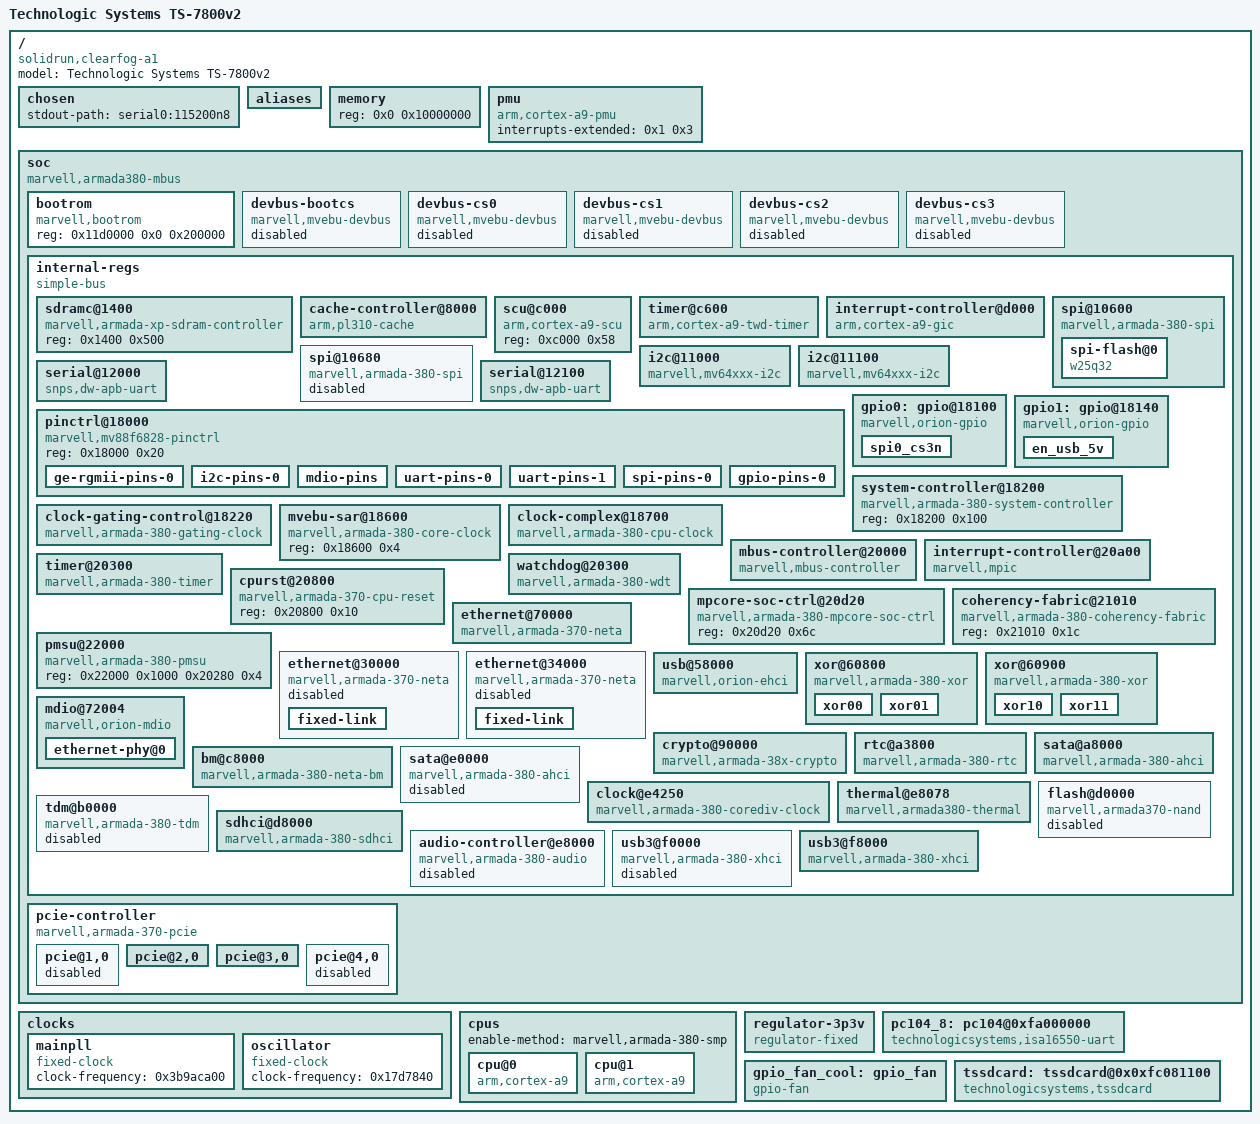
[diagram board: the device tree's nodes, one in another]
/dts-v1/;
#include <dt-bindings/gpio/gpio.h>

/ {
	#address-cells = <0x1>;
	#size-cells = <0x1>;
	model = "Technologic Systems TS-7800v2";
	compatible = "solidrun,clearfog-a1", "marvell,armada388", "marvell,armada385", "marvell,armada380";

	chosen {
		stdout-path = "serial0:115200n8";
	};

	aliases {
		gpio0 = "/soc/internal-regs/gpio@18100";
		gpio1 = "/soc/internal-regs/gpio@18140";
		serial0 = "/soc/internal-regs/serial@12000";
		serial1 = "/soc/internal-regs/serial@12100";
		ethernet1 = "/soc/internal-regs/ethernet@70000";
		ethernet2 = "/soc/internal-regs/ethernet@30000";
		ethernet3 = "/soc/internal-regs/ethernet@34000";
	};

	memory {
		device_type = "memory";
		reg = <0x0 0x10000000>;
	};

	pmu {
		compatible = "arm,cortex-a9-pmu";
		interrupts-extended = <0x1 0x3>;
	};

	soc {
		compatible = "marvell,armada380-mbus", "simple-bus";
		#address-cells = <0x2>;
		#size-cells = <0x1>;
		controller = <0x2>;
		interrupt-parent = <0x3>;
		pcie-mem-aperture = <0xf8000000 0x7e00000>;
		pcie-io-aperture = <0xffe00000 0x100000>;
		ranges = <0xf0010000 0x0 0xf1000000 0x100000 0x11d0000 0x0 0xfff00000 0x100000 0x9190000 0x0 0xf1100000 0x10000 0x9150000 0x0 0xf1110000 0x10000 0xc040000 0x0 0xf1200000 0x100000>;

		bootrom {
			compatible = "marvell,bootrom";
			reg = <0x11d0000 0x0 0x200000>;
		};

		devbus-bootcs {
			compatible = "marvell,mvebu-devbus";
			reg = <0xf0010000 0x10400 0x8>;
			ranges = <0x0 0x12f0000 0x0 0xffffffff>;
			#address-cells = <0x1>;
			#size-cells = <0x1>;
			clocks = <0x4 0x0>;
			status = "disabled";
		};

		devbus-cs0 {
			compatible = "marvell,mvebu-devbus";
			reg = <0xf0010000 0x10408 0x8>;
			ranges = <0x0 0x13e0000 0x0 0xffffffff>;
			#address-cells = <0x1>;
			#size-cells = <0x1>;
			clocks = <0x4 0x0>;
			status = "disabled";
		};

		devbus-cs1 {
			compatible = "marvell,mvebu-devbus";
			reg = <0xf0010000 0x10410 0x8>;
			ranges = <0x0 0x13d0000 0x0 0xffffffff>;
			#address-cells = <0x1>;
			#size-cells = <0x1>;
			clocks = <0x4 0x0>;
			status = "disabled";
		};

		devbus-cs2 {
			compatible = "marvell,mvebu-devbus";
			reg = <0xf0010000 0x10418 0x8>;
			ranges = <0x0 0x13b0000 0x0 0xffffffff>;
			#address-cells = <0x1>;
			#size-cells = <0x1>;
			clocks = <0x4 0x0>;
			status = "disabled";
		};

		devbus-cs3 {
			compatible = "marvell,mvebu-devbus";
			reg = <0xf0010000 0x10420 0x8>;
			ranges = <0x0 0x1370000 0x0 0xffffffff>;
			#address-cells = <0x1>;
			#size-cells = <0x1>;
			clocks = <0x4 0x0>;
			status = "disabled";
		};

		internal-regs {
			compatible = "simple-bus";
			#address-cells = <0x1>;
			#size-cells = <0x1>;
			ranges = <0x0 0xf0010000 0x0 0x100000>;

			sdramc@1400 {
				compatible = "marvell,armada-xp-sdram-controller";
				reg = <0x1400 0x500>;
			};

			cache-controller@8000 {
				compatible = "arm,pl310-cache";
				reg = <0x8000 0x1000>;
				cache-unified;
				cache-level = <0x2>;
				arm,double-linefill-incr = <0x1>;
				arm,double-linefill-wrap = <0x0>;
				arm,double-linefill = <0x1>;
				prefetch-data = <0x1>;
			};

			scu@c000 {
				compatible = "arm,cortex-a9-scu";
				reg = <0xc000 0x58>;
			};

			timer@c600 {
				compatible = "arm,cortex-a9-twd-timer";
				reg = <0xc600 0x20>;
				interrupts = <0x1 0xd 0x301>;
				clocks = <0x4 0x2>;
			};

			interrupt-controller@d000 {
				compatible = "arm,cortex-a9-gic";
				#interrupt-cells = <0x3>;
				#size-cells = <0x0>;
				interrupt-controller;
				reg = <0xd000 0x1000 0xc100 0x100>;
				linux,phandle = <0x3>;
				phandle = <0x3>;
			};

			spi@10600 {
				compatible = "marvell,armada-380-spi", "marvell,orion-spi";
				reg = <0x10600 0x50>;
				#address-cells = <0x1>;
				#size-cells = <0x0>;
				cell-index = <0x0>;
				interrupts = <0x0 0x1 0x4>;
				clocks = <0x4 0x0>;
				status = "okay";
				cs-gpios = <0>, <0>, <0>, <&gpio0 28 0>;

				spi-flash@0 {
					#address-cells = <0x1>;
					#size-cells = <0x1>;
					compatible = "w25q32", "jedec,spi-nor";
					reg = <0x3>;
					spi-max-frequency = <0x2dc6c0>;
					status = "okay";
				};
			};

			spi@10680 {
				compatible = "marvell,armada-380-spi", "marvell,orion-spi";
				reg = <0x10680 0x50>;
				#address-cells = <0x1>;
				#size-cells = <0x0>;
				cell-index = <0x1>;
				interrupts = <0x0 0x3f 0x4>;
				clocks = <0x4 0x0>;
				status = "disabled";
				pinctrl-0 = <0x5 0x6 0x7>;
				pinctrl-names = "default";

//				spi-flash@3 {
//					#address-cells = <0x1>;
//					#size-cells = <0x1>;
//					compatible = "w25q32", "jedec,spi-nor";
//					reg = <0x0>;
//					spi-max-frequency = <0x2dc6c0>;
//					status = "okay";
//				};

//				slic@1 {
//					#address-cells = <0x1>;
//					#size-cells = <0x0>;
//					compatible = "mv_slic";
//					reg = <0x1>;
//					spi-max-frequency = <0x2dc6c0>;
//					spi-1byte-cs;
//					spi-cpol;
//					spi-cpha;
//				};
			};

			i2c@11000 {
				compatible = "marvell,mv64xxx-i2c";
				reg = <0x11000 0x20>;
				#address-cells = <0x1>;
				#size-cells = <0x0>;
				interrupts = <0x0 0x2 0x4>;
				timeout-ms = <0x3e8>;
				clocks = <0x4 0x0>;
				status = "okay";
				clock-frequency = <0x186a0>;
				pinctrl-0 = <0x8>;
				pinctrl-names = "default";

//				gpio-expander@20 {
//					compatible = "nxp,pca9555";
//					gpio-controller;
//					#gpio-cells = <0x2>;
//					reg = <0x20>;
//					linux,phandle = <0x1c>;
//					phandle = <0x1c>;
//
//					pcie1_0_clkreq {
//						gpio-hog;
//						gpios = <0x0 0x1>;
//						input;
//						line-name = "pcie1.0-clkreq";
//					};
//
//					pcie1_0_w_disable {
//						gpio-hog;
//						gpios = <0x3 0x1>;
//						output-low;
//						line-name = "pcie1.0-w-disable";
//					};
//
//					pcie2_0_clkreq {
//						gpio-hog;
//						gpios = <0x4 0x1>;
//						input;
//						line-name = "pcie2.0-clkreq";
//					};
//
//					pcie2_0_w_disable {
//						gpio-hog;
//						gpios = <0x7 0x1>;
//						output-low;
//						line-name = "pcie2.0-w-disable";
//					};
//
//					usb3_ilimit {
//						gpio-hog;
//						gpios = <0x5 0x1>;
//						input;
//						line-name = "usb3-current-limit";
//					};
//
//					usb3_power {
//						gpio-hog;
//						gpios = <0x6 0x0>;
//						output-high;
//						line-name = "usb3-power";
//					};
//
//					m2_devslp {
//						gpio-hog;
//						gpios = <0xb 0x0>;
//						output-low;
//						line-name = "m.2 devslp";
//					};
//
//					sfp_los {
//						gpio-hog;
//						gpios = <0xc 0x0>;
//						input;
//						line-name = "sfp-los";
//					};
//
//					sfp_tx_fault {
//						gpio-hog;
//						gpios = <0xd 0x0>;
//						input;
//						line-name = "sfp-tx-fault";
//					};
//
//					sfp_tx_disable {
//						gpio-hog;
//						gpios = <0xe 0x0>;
//						output-low;
//						line-name = "sfp-tx-disable";
//					};
//
//					sfp_mod_def0 {
//						gpio-hog;
//						gpios = <0xf 0x1>;
//						input;
//						line-name = "sfp-mod-def0";
//					};
//				};
//
//				mcp3021@4c {
//					compatible = "microchip,mcp3021";
//					reg = <0x4c>;
//				};
			};

			i2c@11100 {
				compatible = "marvell,mv64xxx-i2c";
				reg = <0x11100 0x20>;
				#address-cells = <0x1>;
				#size-cells = <0x0>;
				interrupts = <0x0 0x3 0x4>;
				timeout-ms = <0x3e8>;
				clocks = <0x4 0x0>;
				status = "okay";
				clock-frequency = <0x186a0>;
				pinctrl-0 = <0x9>;
				pinctrl-names = "default";
			};

			serial@12000 {
				compatible = "snps,dw-apb-uart";
				reg = <0x12000 0x100>;
				reg-shift = <0x2>;
				interrupts = <0x0 0xc 0x4>;
				reg-io-width = <0x1>;
				clocks = <0x4 0x0>;
				status = "okay";
				pinctrl-0 = <0xa>;
				pinctrl-names = "default";
			};

			serial@12100 {
				compatible = "snps,dw-apb-uart";
				reg = <0x12100 0x100>;
				reg-shift = <0x2>;
				interrupts = <0x0 0xd 0x4>;
				reg-io-width = <0x1>;
				clocks = <0x4 0x0>;
				status = "okay";
				pinctrl-0 = <0xb>;
				pinctrl-names = "default";
			};

			pinctrl@18000 {
				reg = <0x18000 0x20>;
				compatible = "marvell,mv88f6828-pinctrl";


				ge-rgmii-pins-0 {
					marvell,pins = "mpp6", "mpp7", "mpp8", "mpp9", "mpp10", "mpp11", "mpp12", "mpp13", "mpp14", "mpp15", "mpp16", "mpp17";
					marvell,function = "ge0";
					linux,phandle = <0xe>;
					phandle = <0xe>;
				};

				i2c-pins-0 {
					marvell,pins = "mpp2", "mpp3";
					marvell,function = "i2c0";
					linux,phandle = <0x8>;
					phandle = <0x8>;
				};

				mdio-pins {
					marvell,pins = "mpp4", "mpp5";
					marvell,function = "ge";
					linux,phandle = <0x11>;
					phandle = <0x11>;
				};

				uart-pins-0 {
					marvell,pins = "mpp0", "mpp1";
					marvell,function = "ua0";
					linux,phandle = <0xa>;
					phandle = <0xa>;
				};

				uart-pins-1 {
					marvell,pins = "mpp19", "mpp20";
					marvell,function = "ua1";
				};

				spi-pins-0 {
					marvell,pins = "mpp22", "mpp23", "mpp24", "mpp25", "mpp26", "mpp27";
					marvell,function = "spi0";
				};

				gpio-pins-0 {
					marvell,pins = "mpp28", "mpp45";
					marvell,function = "gpio";
				};


			};

			gpio0: gpio@18100 {
				compatible = "marvell,orion-gpio";
				reg = <0x18100 0x40>;
				ngpios = <0x20>;
				gpio-controller;
				#gpio-cells = <0x2>;
				interrupt-controller;
				#interrupt-cells = <0x2>;
				interrupts = <0x0 0x35 0x4 0x0 0x36 0x4 0x0 0x37 0x4 0x0 0x38 0x4>;
				linux,phandle = <0x18>;
				phandle = <0x18>;

				spi0_cs3n {
					gpio-hog;
					gpios = <28 0x0>;
					output-high;
					line-name = "spi0-cs3n";
				};
			};

			gpio1: gpio@18140 {
				compatible = "marvell,orion-gpio";
				reg = <0x18140 0x40>;
				ngpios = <0x1c>;
				gpio-controller;
				#gpio-cells = <0x2>;
				interrupt-controller;
				#interrupt-cells = <0x2>;
				interrupts = <0x0 0x3a 0x4 0x0 0x3b 0x4 0x0 0x3c 0x4 0x0 0x3d 0x4>;
				linux,phandle = <0x23>;
				phandle = <0x23>;

				en_usb_5v {
					gpio-hog;
					gpios = <13 0x0>;
					output-high;
					line-name = "en-usb-5v";
				};
			};

			system-controller@18200 {
				compatible = "marvell,armada-380-system-controller", "marvell,armada-370-xp-system-controller";
				reg = <0x18200 0x100>;
			};

			clock-gating-control@18220 {
				compatible = "marvell,armada-380-gating-clock";
				reg = <0x18220 0x4>;
				clocks = <0x4 0x0>;
				#clock-cells = <0x1>;
				linux,phandle = <0xd>;
				phandle = <0xd>;
			};

			mvebu-sar@18600 {
				compatible = "marvell,armada-380-core-clock";
				reg = <0x18600 0x4>;
				#clock-cells = <0x1>;
				linux,phandle = <0x4>;
				phandle = <0x4>;
			};

			clock-complex@18700 {
				compatible = "marvell,armada-380-cpu-clock", "marvell,armada-xp-cpu-clock";
				reg = <0x18700 0xa0 0x1c054 0x40 0xe4260 0x8>;
				clocks = <0x4 0x1>;
				#clock-cells = <0x1>;
				linux,phandle = <0x1d>;
				phandle = <0x1d>;
			};

			mbus-controller@20000 {
				compatible = "marvell,mbus-controller";
				reg = <0x20000 0x100 0x20180 0x20 0x20250 0x8 0x20420 0xc>;
				linux,phandle = <0x2>;
				phandle = <0x2>;
			};

			interrupt-controller@20a00 {
				compatible = "marvell,mpic";
				reg = <0x20a00 0x2d0 0x21070 0x58>;
				#interrupt-cells = <0x1>;
				#size-cells = <0x1>;
				interrupt-controller;
				msi-controller;
				interrupts = <0x1 0xf 0x4>;
				linux,phandle = <0x1>;
				phandle = <0x1>;
			};

			timer@20300 {
				compatible = "marvell,armada-380-timer", "marvell,armada-xp-timer";
				reg = <0x20300 0x30 0x21040 0x30>;
				interrupts-extended = <0x3 0x0 0x8 0x4 0x3 0x0 0x9 0x4 0x3 0x0 0xa 0x4 0x3 0x0 0xb 0x4 0x1 0x5 0x1 0x6>;
				clocks = <0x4 0x2 0xc>;
				clock-names = "nbclk", "fixed";
			};

			watchdog@20300 {
				compatible = "marvell,armada-380-wdt";
				reg = <0x20300 0x34 0x20704 0x4 0x18260 0x4>;
				clocks = <0x4 0x2 0xc>;
				clock-names = "nbclk", "fixed";
			};

			cpurst@20800 {
				compatible = "marvell,armada-370-cpu-reset";
				reg = <0x20800 0x10>;
			};

			mpcore-soc-ctrl@20d20 {
				compatible = "marvell,armada-380-mpcore-soc-ctrl";
				reg = <0x20d20 0x6c>;
			};

			coherency-fabric@21010 {
				compatible = "marvell,armada-380-coherency-fabric";
				reg = <0x21010 0x1c>;
			};

			pmsu@22000 {
				compatible = "marvell,armada-380-pmsu";
				reg = <0x22000 0x1000 0x20280 0x4>;
			};

			ethernet@70000 {
				compatible = "marvell,armada-370-neta";
				reg = <0x70000 0x4000>;
				interrupts-extended = <0x1 0x8>;
				clocks = <0xd 0x4>;
				tx-csum-limit = <0x2648>;
				status = "okay";
				pinctrl-0 = <0xe>;
				pinctrl-names = "default";
				phy = <0xf>;
				phy-mode = "rgmii-id";
				buffer-manager = <0x10>;
				bm,pool-long = <0x0>;
				bm,pool-short = <0x1>;
			};

			ethernet@30000 {
				compatible = "marvell,armada-370-neta";
				reg = <0x30000 0x4000>;
				interrupts-extended = <0x1 0xa>;
				clocks = <0xd 0x3>;
				status = "disabled";
				phy-mode = "sgmii";
				buffer-manager = <0x10>;
				bm,pool-long = <0x2>;
				bm,pool-short = <0x1>;
				linux,phandle = <0x1e>;
				phandle = <0x1e>;

				fixed-link {
					speed = <0x3e8>;
					full-duplex;
				};
			};

			ethernet@34000 {
				compatible = "marvell,armada-370-neta";
				reg = <0x34000 0x4000>;
				interrupts-extended = <0x1 0xc>;
				clocks = <0xd 0x2>;
				status = "disabled";
				phy-mode = "sgmii";
				buffer-manager = <0x10>;
				bm,pool-long = <0x3>;
				bm,pool-short = <0x1>;

				fixed-link {
					speed = <0x3e8>;
					full-duplex;
				};
			};

			usb@58000 {
				compatible = "marvell,orion-ehci";
				reg = <0x58000 0x500>;
				interrupts = <0x0 0x12 0x4>;
				clocks = <0xd 0x12>;
				status = "okay";
			};

			xor@60800 {
				compatible = "marvell,armada-380-xor", "marvell,orion-xor";
				reg = <0x60800 0x100 0x60a00 0x100>;
				clocks = <0xd 0x16>;
				status = "okay";

				xor00 {
					interrupts = <0x0 0x16 0x4>;
					dmacap,memcpy;
					dmacap,xor;
				};

				xor01 {
					interrupts = <0x0 0x17 0x4>;
					dmacap,memcpy;
					dmacap,xor;
					dmacap,memset;
				};
			};

			xor@60900 {
				compatible = "marvell,armada-380-xor", "marvell,orion-xor";
				reg = <0x60900 0x100 0x60b00 0x100>;
				clocks = <0xd 0x1c>;
				status = "okay";

				xor10 {
					interrupts = <0x0 0x41 0x4>;
					dmacap,memcpy;
					dmacap,xor;
				};

				xor11 {
					interrupts = <0x0 0x42 0x4>;
					dmacap,memcpy;
					dmacap,xor;
					dmacap,memset;
				};
			};

			mdio@72004 {
				#address-cells = <0x1>;
				#size-cells = <0x0>;
				compatible = "marvell,orion-mdio";
				reg = <0x72004 0x4>;
				clocks = <0xd 0x4>;
				pinctrl-0 = <0x11>;
				pinctrl-names = "default";
				linux,phandle = <0x1f>;
				phandle = <0x1f>;
				status = "okay";

				ethernet-phy@0 {
					marvell,reg-init = <0x3 0x10 0x0 0x101e>;
					reg = <0x1>;
					linux,phandle = <0xf>;
					phandle = <0xf>;
				};
			};

			crypto@90000 {
				compatible = "marvell,armada-38x-crypto";
				reg = <0x90000 0x10000>;
				reg-names = "regs";
				interrupts = <0x0 0x13 0x4 0x0 0x14 0x4>;
				clocks = <0xd 0x17 0xd 0x15 0xd 0xe 0xd 0x10>;
				clock-names = "cesa0", "cesa1", "cesaz0", "cesaz1";
				marvell,crypto-srams = <0x12 0x13>;
				marvell,crypto-sram-size = <0x800>;
			};

			rtc@a3800 {
				compatible = "marvell,armada-380-rtc";
				reg = <0xa3800 0x20 0x184a0 0xc>;
				reg-names = "rtc", "rtc-soc";
				interrupts = <0x0 0x15 0x4>;
				status = "okay";
			};

			sata@a8000 {   /* SATA 0 & 1 */
				compatible = "marvell,armada-380-ahci";
				reg = <0xa8000 0x2000>;
				interrupts = <0x0 0x1a 0x4>;
				clocks = <0xd 0xf>;
				status = "okay";
			};

			bm@c8000 {
				compatible = "marvell,armada-380-neta-bm";
				reg = <0xc8000 0xac>;
				clocks = <0xd 0xd>;
				internal-mem = <0x14>;
				status = "okay";
				linux,phandle = <0x10>;
				phandle = <0x10>;
			};

			sata@e0000 {  /* SATA 2 & 3, not present on 88F6820 */
				compatible = "marvell,armada-380-ahci";
				reg = <0xe0000 0x2000>;
				interrupts = <0x0 0x1c 0x4>;
				clocks = <0xd 0x1e>;
				status = "disabled";
			};

			clock@e4250 {
				compatible = "marvell,armada-380-corediv-clock";
				reg = <0xe4250 0xc>;
				#clock-cells = <0x1>;
				clocks = <0x15>;
				clock-output-names = "nand";
				linux,phandle = <0x16>;
				phandle = <0x16>;
			};

			thermal@e8078 {
				compatible = "marvell,armada380-thermal";
				reg = <0xe4078 0x4 0xe4070 0x8 0xe4100 0x20>;
				interrupts = <0x0 0x4e 0x4>;
				threshold = <0x64>;
				hysteresis = <0x2>;
				status = "okay";
			};

			flash@d0000 {
				compatible = "marvell,armada370-nand";
				reg = <0xd0000 0x54>;
				#address-cells = <0x1>;
				#size-cells = <0x1>;
				interrupts = <0x0 0x54 0x4>;
				clocks = <0x16 0x0>;
				status = "disabled";
			};

			tdm@b0000 {
				compatible = "marvell,armada-380-tdm";
				reg = <0xb0000 0x5000 0x18400 0xc 0x18730 0x4>;
				reg-names = "tdm_regs", "pll_regs", "dco_div";
				interrupts = <0x0 0x1b 0x4>;
				clocks = <0xd 0x19>;
				clock-names = "gateclk";
				status = "disabled";
				pinctrl-0 = <0x17>;
				pinctrl-names = "default";
				pclk-freq-mhz = <0x8>;
			};

			sdhci@d8000 {
				compatible = "marvell,armada-380-sdhci";
				reg-names = "sdhci", "mbus", "conf-sdio3";
				reg = <0xd8000 0x1000 0xdc000 0x100 0x18454 0x4>;
				interrupts = <0x0 0x19 0x4>;
				clocks = <0xd 0x11>;
				mrvl,clk-delay-cycles = <0x1f>;
				status = "okay";
				bus-width = <0x4>;
				cd-gpios = <0x18 0x14 0x1>;
				no-1-8-v;
				pinctrl-0 = <0x19 0x1a>;
				pinctrl-names = "default";
				vmmc = <0x1b>;
				wp-inverted;
			};

			audio-controller@e8000 {
				#sound-dai-cells = <0x1>;
				compatible = "marvell,armada-380-audio";
				reg = <0xe8000 0x4000 0x18410 0xc 0x18204 0x4>;
				reg-names = "i2s_regs", "pll_regs", "soc_ctrl";
				interrupts = <0x0 0x4b 0x4>;
				clocks = <0xd 0x0>;
				clock-names = "internal";
				status = "disabled";
			};

			usb3@f0000 {
				compatible = "marvell,armada-380-xhci";
				reg = <0xf0000 0x4000 0xf4000 0x4000>;
				interrupts = <0x0 0x10 0x4>;
				clocks = <0xd 0x9>;
				status = "disabled";
			};

			usb3@f8000 {
				compatible = "marvell,armada-380-xhci";
				reg = <0xf8000 0x4000 0xfc000 0x4000>;
				interrupts = <0x0 0x11 0x4>;
				clocks = <0xd 0xa>;
				status = "okay";
			};
		};

//		sa-sram0 {
//			compatible = "mmio-sram";
//			reg = <0x9190000 0x0 0x800>;
//			clocks = <0xd 0x17>;
//			#address-cells = <0x1>;
//			#size-cells = <0x1>;
//			ranges = <0x0 0x9190000 0x0 0x800>;
//			linux,phandle = <0x12>;
//			phandle = <0x12>;
//		};
//
//		sa-sram1 {
//			compatible = "mmio-sram";
//			reg = <0x9150000 0x0 0x800>;
//			clocks = <0xd 0x15>;
//			#address-cells = <0x1>;
//			#size-cells = <0x1>;
//			ranges = <0x0 0x9150000 0x0 0x800>;
//			linux,phandle = <0x13>;
//			phandle = <0x13>;
//		};
//
//		bm-bppi {
//			compatible = "mmio-sram";
//			reg = <0xc040000 0x0 0x100000>;
//			ranges = <0x0 0xc040000 0x0 0x100000>;
//			#address-cells = <0x1>;
//			#size-cells = <0x1>;
//			clocks = <0xd 0xd>;
//			no-memory-wc;
//			status = "okay";
//			linux,phandle = <0x14>;
//			phandle = <0x14>;
//		};

		pcie-controller {
			compatible = "marvell,armada-370-pcie";
			status = "okay";
			device_type = "pci";
			#address-cells = <0x3>;
			#size-cells = <0x2>;
			msi-parent = <0x1>;
			bus-range = <0x0 0xff>;
			ranges = <0x82000000 0x0 0x80000 0xf0010000 0x80000 0x0 0x2000 0x82000000 0x0 0x40000 0xf0010000 0x40000 0x0 0x2000 0x82000000 0x0 0x44000 0xf0010000 0x44000 0x0 0x2000 0x82000000 0x0 0x48000 0xf0010000 0x48000 0x0 0x2000 0x82000000 0x1 0x0 0x8e80000 0x0 0x1 0x0 0x81000000 0x1 0x0 0x8e00000 0x0 0x1 0x0 0x82000000 0x2 0x0 0x4e80000 0x0 0x1 0x0 0x81000000 0x2 0x0 0x4e00000 0x0 0x1 0x0 0x82000000 0x3 0x0 0x4d80000 0x0 0x1 0x0 0x81000000 0x3 0x0 0x4d00000 0x0 0x1 0x0 0x82000000 0x4 0x0 0x4b80000 0x0 0x1 0x0 0x81000000 0x4 0x0 0x4b00000 0x0 0x1 0x0>;

			pcie@1,0 {
				device_type = "pci";
				assigned-addresses = <0x82000800 0x0 0x80000 0x0 0x2000>;
				reg = <0x800 0x0 0x0 0x0 0x0>;
				#address-cells = <0x3>;
				#size-cells = <0x2>;
				#interrupt-cells = <0x1>;
				ranges = <0x82000000 0x0 0x0 0x82000000 0x1 0x0 0x1 0x0 0x81000000 0x0 0x0 0x81000000 0x1 0x0 0x1 0x0>;
				interrupt-map-mask = <0x0 0x0 0x0 0x0>;
				interrupt-map = <0x0 0x0 0x0 0x0 0x3 0x0 0x1d 0x4>;
				marvell,pcie-port = <0x0>;
				marvell,pcie-lane = <0x0>;
				clocks = <0xd 0x8>;
				status = "disabled";
			};

			pcie@2,0 {
				device_type = "pci";
				assigned-addresses = <0x82000800 0x0 0x40000 0x0 0x2000>;
				reg = <0x1000 0x0 0x0 0x0 0x0>;
				#address-cells = <0x3>;
				#size-cells = <0x2>;
				#interrupt-cells = <0x1>;
				ranges = <0x82000000 0x0 0x0 0x82000000 0x2 0x0 0x1 0x0 0x81000000 0x0 0x0 0x81000000 0x2 0x0 0x1 0x0>;
				interrupt-map-mask = <0x0 0x0 0x0 0x0>;
				interrupt-map = <0x0 0x0 0x0 0x0 0x3 0x0 0x21 0x4>;
				marvell,pcie-port = <0x1>;
				marvell,pcie-lane = <0x0>;
				clocks = <0xd 0x5>;
				status = "okay";
				reset-gpios = <0x1c 0x1 0x1>;
			};

			pcie@3,0 {
				device_type = "pci";
				assigned-addresses = <0x82000800 0x0 0x44000 0x0 0x2000>;
				reg = <0x1800 0x0 0x0 0x0 0x0>;
				#address-cells = <0x3>;
				#size-cells = <0x2>;
				#interrupt-cells = <0x1>;
				ranges = <0x82000000 0x0 0x0 0x82000000 0x3 0x0 0x1 0x0 0x81000000 0x0 0x0 0x81000000 0x3 0x0 0x1 0x0>;
				interrupt-map-mask = <0x0 0x0 0x0 0x0>;
				interrupt-map = <0x0 0x0 0x0 0x0 0x3 0x0 0x46 0x4>;
				marvell,pcie-port = <0x2>;
				marvell,pcie-lane = <0x0>;
				clocks = <0xd 0x6>;
				status = "okay";
				reset-gpios = <0x1c 0x2 0x1>;
			};

			pcie@4,0 {
				device_type = "pci";
				assigned-addresses = <0x82000800 0x0 0x48000 0x0 0x2000>;
				reg = <0x2000 0x0 0x0 0x0 0x0>;
				#address-cells = <0x3>;
				#size-cells = <0x2>;
				#interrupt-cells = <0x1>;
				ranges = <0x82000000 0x0 0x0 0x82000000 0x4 0x0 0x1 0x0 0x81000000 0x0 0x0 0x81000000 0x4 0x0 0x1 0x0>;
				interrupt-map-mask = <0x0 0x0 0x0 0x0>;
				interrupt-map = <0x0 0x0 0x0 0x0 0x3 0x0 0x47 0x4>;
				marvell,pcie-port = <0x3>;
				marvell,pcie-lane = <0x0>;
				clocks = <0xd 0x7>;
				status = "disabled";
			};
		};
	};

	clocks {

		mainpll {
			compatible = "fixed-clock";
			#clock-cells = <0x0>;
			clock-frequency = <0x3b9aca00>;
			linux,phandle = <0x15>;
			phandle = <0x15>;
		};

		oscillator {
			compatible = "fixed-clock";
			#clock-cells = <0x0>;
			clock-frequency = <0x17d7840>;
			linux,phandle = <0xc>;
			phandle = <0xc>;
		};
	};

	cpus {
		#address-cells = <0x1>;
		#size-cells = <0x0>;
		enable-method = "marvell,armada-380-smp";

		cpu@0 {
			device_type = "cpu";
			compatible = "arm,cortex-a9";
			reg = <0x0>;
			clocks = <0x1d 0x0>;
			clock-latency = <0xf4240>;
			clock-names = "cpu0";
		};

		cpu@1 {
			device_type = "cpu";
			compatible = "arm,cortex-a9";
			reg = <0x1>;
			clocks = <0x1d 0x0>;
			clock-latency = <0xf4240>;
			clock-names = "cpu1";
		};
	};

	regulator-3p3v {
		compatible = "regulator-fixed";
		regulator-name = "3P3V";
		regulator-min-microvolt = <0x325aa0>;
		regulator-max-microvolt = <0x325aa0>;
		regulator-always-on;
		linux,phandle = <0x1b>;
		phandle = <0x1b>;
	};

	pc104_8: pc104@0xfa000000 {
	   compatible = "technologicsystems,isa16550-uart";
	   #address-cells = <0x1>;
		#size-cells = <0x0>;
	   reg = <0xfa000000 0x1000>;
	   interrupts = <6>;
	   status = "okay";
	};
	
	
	gpio_fan_cool: gpio_fan {
		compatible = "gpio-fan";
		gpios = <&gpio1 7 GPIO_ACTIVE_LOW>;			 
		gpio-fan,speed-map =	<0    0>,
					<3000 1>,
					<6000 2>;		
		#cooling-cells = <2>; /* min followed by max */
	};

	
	tssdcard: tssdcard@0x0xfc081100 {
	   compatible = "technologicsystems,tssdcard";
	   #address-cells = <0x1>;
		#size-cells = <0x0>;
	   reg = <0xfc081100 16>;
	   tssdcard,ndevices = <1>;	   
	   status = "okay";
	};
	
};
